# R7FA2A2AD register map
Vendor: Renesas Electronics Corporation; Series: RA2A2; File version: 1.20.02
CPU: CM23 r1p0, little endian, MPU, no FPU, VTOR, 2 interrupt priority bits, 32 interrupts
Registers are 8-bit, read-write, reset 0x0 unless marked. A register's access mark holds for its fields unless they carry their own. Offsets are from the block's base; [hi:lo] are bit positions; {n}, {i} and the like mark numbered series; 'fields as' and 'values as' point back to an identical list; <NAME> marks a mode.

## SYSC — System Control
Base 0x4001E000
0x0C SBYCR 16-bit — Standby Control Register
  [15] SSBY — Software Standby Mode Select
    0=Sleep mode; 1=Software Standby mode
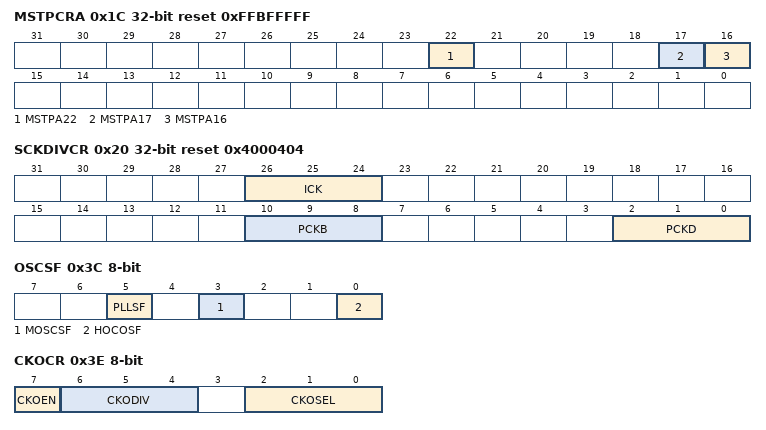
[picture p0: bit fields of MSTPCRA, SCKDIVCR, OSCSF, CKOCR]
0x1C MSTPCRA 32-bit reset 0xFFBFFFFF — Module Stop Control Register A
  [22] MSTPA22 — DTC Module Stop
    0=Cancel the module-stop state; 1=Enter the module-stop state
  [17] MSTPA17 — Main Oscillation Stop Detection for SDADCCLK Module Stop
    0=Supply input clock. SFR used by MOSTD can be read/written.; 1=Stop supply of input clock. SFR used by MOSTD cannot be written. MOSTD clock is stopped and error flag is in the reset status.
  [16] MSTPA16 — Sub Oscillation Stop Detection for SDADCCLK Module Stop
    0=Supply input clock. SFR used by SOSTD can be read/written.; 1=Stop supply of input clock. SFR used by SOSTD cannot be written. SOSTD clock is stopped and error flag is in the reset status.
0x20 SCKDIVCR 32-bit reset 0x4000404 — System Clock Division Control Register
  [all] fields
    0=x 1/1; 1=x 1/2; 2=x 1/4; 3=x 1/8; 4=x 1/16; 5=x 1/32; 6=x 1/64; other=Others (Settings prohibited)
  [26:24] ICK — System Clock (ICLK) Select
  [10:8] PCKB — Peripheral Module Clock B (PCLKB) Select
  [2:0] PCKD — Peripheral Module Clock D (PCLKD) Select
0x26 SCKSCR reset 0x1 — System Clock Source Control Register
  [2:0] CKSEL — Clock Source Select
    0=HOCO; 1=MOCO; 2=LOCO; 3=Main clock oscillator (MOSC); 4=Sub-clock oscillator (SOSC); 5=Setting prohibited; 6=Setting prohibited; 7=Setting prohibited
0x28 PLLCCR 16-bit reset 0x9E04 — PLL Clock Control Register
  [15:8] PLLMUL — PLL Frequency Multiplication Factor Select
    158=× 732 (value after reset); 207=× 781; other=Others (Setting prohibited)
0x2A PLLCR reset 0x1 — PLL Control Register
  [0] PLLSTP — PLL Stop Control
    0=PLL is operating; 1=PLL is stopped
0x31 MEMWAIT — Memory Wait Cycle Control Register for Code Flash
  [0] MEMWAIT — Memory Wait Cycle Select for Code Flash
    0=No wait; 1=Wait
0x32 MOSCCR reset 0x1 — Main Clock Oscillator Control Register
  [0] MOSTP — Main Clock Oscillator Stop
    0=Operate the main clock oscillator; 1=Stop the main clock oscillator
0x36 HOCOCR (reset mask 0xFE) — High-Speed On-Chip Oscillator Control Register
  [0] HCSTP — HOCO Stop
    0=Operate the HOCO clock; 1=Stop the HOCO clock
0x38 MOCOCR — Middle-Speed On-Chip Oscillator Control Register
  [0] MCSTP — MOCO Stop
    0=MOCO clock is operating; 1=MOCO clock is stopped
0x3C OSCSF ro (reset mask 0xFE) — Oscillation Stabilization Flag Register
  [5] PLLSF — PLL Clock Oscillation Stabilization Flag
    0=The PLL clock is stopped or oscillation of the PLL clock is not yet stable; 1=The PLL clock is stable, so is available for use as the SDADCCLK clock
  [3] MOSCSF — Main Clock Oscillation Stabilization Flag
    0=The main clock oscillator is stopped (MOSTP = 1) or is not yet stable; 1=The main clock oscillator is stable, so is available for use as the system clock
  [0] HOCOSF — HOCO Clock Oscillation Stabilization Flag
    0=The HOCO clock is stopped or is not yet stable; 1=The HOCO clock is stable, so is available for use as the system clock
0x3E CKOCR — Clock Out Control Register
  [7] CKOEN — Clock Out Enable
    0=Disable clock out; 1=Enable clock out
  [6:4] CKODIV — Clock Output Frequency Division Ratio
    0=x 1/1; 1=x 1/2; 2=x 1/4; 3=x 1/8; 4=x 1/16; 5=x 1/32; 6=x 1/64; 7=x 1/128
  [2:0] CKOSEL — Clock Out Source Select
    0=HOCO (value after reset); 1=MOCO; 2=LOCO; 3=MOSC; 4=SOSC; 5=PLL; other=Others (Setting prohibited)
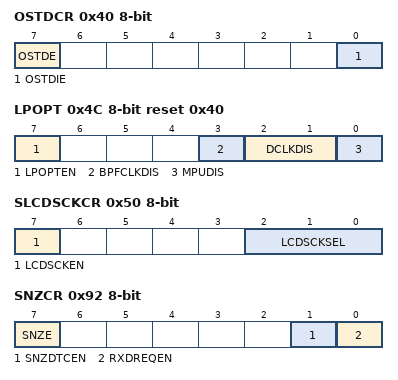
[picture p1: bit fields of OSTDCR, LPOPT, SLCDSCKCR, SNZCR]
0x40 OSTDCR — Oscillation Stop Detection Control Register
  [7] OSTDE — Oscillation Stop Detection Function Enable
    0=Disable oscillation stop detection function; 1=Enable oscillation stop detection function
  [0] OSTDIE — Oscillation Stop Detection Interrupt Enable
    0=Disable oscillation stop detection interrupt (do not notify the POEG); 1=Enable oscillation stop detection interrupt (notify the POEG)
0x41 OSTDSR — Oscillation Stop Detection Status Register
  [0] OSTDF — Oscillation Stop Detection Flag
    0=Main clock oscillation stop not detected; 1=Main clock oscillation stop detected
0x4C LPOPT reset 0x40 — Lower Power Operation Control Register
  [7] LPOPTEN — Lower Power Operation Enable
    0=All lower power counter measure disable; 1=All lower power counter measure enable
  [3] BPFCLKDIS — BPF Clock Disable Control
    0=Flash register R/W clock operates as normal; 1=Flash register R/W clock stops
  [2:1] DCLKDIS — Debug Clock Disable Control
    0=Debug clock does not stop; other=Others (Debug clock stops (valid only when LPOPT.LPOPTEN = 1))
  [0] MPUDIS — MPU Clock Disable Control
    0=MPU operates as normal; 1=MPU operate clock stops (MPU function disable)
0x50 SLCDSCKCR — Segment LCD Source Clock Control Register
  [7] LCDSCKEN — LCD Source Clock Out Enable
    0=LCD source clock out disabled; 1=LCD source clock out enabled
  [2:0] LCDSCKSEL — LCD Source Clock (LCDSRCCLK) Select
    0=LOCO; 1=SOSC; 2=MOSC; 3=MOCO; 4=HOCO; other=Others (Setting prohibited)
0x61 MOCOUTCR — MOCO User Trimming Control Register
  [7:0] MOCOUTRM — MOCO User Trimming
0x62 HOCOUTCR — HOCO User Trimming Control Register
  [7:0] HOCOUTRM — HOCO User Trimming
0x92 SNZCR — Snooze Control Register
  [7] SNZE — Snooze mode Enable
    0=Disable Snooze mode; 1=Enable Snooze mode
  [1] SNZDTCEN — DTC Enable in Snooze mode
    0=Disable DTC operation; 1=Enable DTC operation
  [0] RXDREQEN — RXD0 Snooze Request Enable
    0=Ignore RXD0 falling edge in Software Standby mode; 1=Detect RXD0 falling edge in Software Standby mode
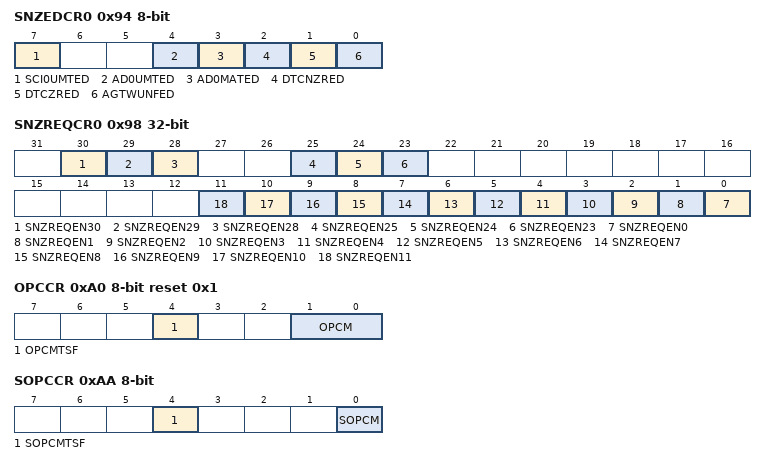
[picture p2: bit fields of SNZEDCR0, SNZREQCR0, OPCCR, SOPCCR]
0x94 SNZEDCR0 — Snooze End Control Register 0
  [all] fields
    0=Disable the snooze end request; 1=Enable the snooze end request
  [7] SCI0UMTED — SCI0 Address Mismatch Snooze End Enable
  [4] AD0UMTED — ADC12 Compare Mismatch Snooze End Enable
  [3] AD0MATED — ADC12 Compare Match Snooze End Enable
  [2] DTCNZRED — Not Last DTC Transmission Completion Snooze End Enable
  [1] DTCZRED — Last DTC Transmission Completion Snooze End Enable
  [0] AGTWUNFED — AGTW1 Underflow Snooze End Enable
0x98 SNZREQCR0 32-bit — Snooze Request Control Register 0
  [all] fields
    0=Disable the snooze request; 1=Enable the snooze request
  [30] SNZREQEN30 — Enable AGTW1 Compare Match B Snooze Request
  [29] SNZREQEN29 — Enable AGTW1 Compare Match A Snooze Request
  [28] SNZREQEN28 — Enable AGTW1 Underflow Snooze Request
  [25] SNZREQEN25 — Enable RTC Period Snooze Request
  [24] SNZREQEN24 — Enable RTC Alarm 0 Snooze Request
  [23] SNZREQEN23 — Enable RTC Alarm 1 Snooze Request
  [n] SNZREQEN{n} (n=0..11) — Enable IRQ{n} Pin Snooze Request
0x9F PSMCR — Power Save Memory Control Register
  [1:0] PSMC — Power Save Memory Control
    0=All SRAMs are on in Software Standby mode; 1=8 KB SRAM (0x2000_4000 to 0x2000_5FFF) is on in Software Standby mode; 2=Setting prohibited; 3=Setting prohibited
0xA0 OPCCR reset 0x1 — Operating Power Control Register
  [4] OPCMTSF ro — Operating Power Control Mode Transition Status Flag
    0=Transition completed; 1=During transition
  [1:0] OPCM — Operating Power Control Mode Select
    0=High-speed mode; 1=Middle-speed mode; 2=Setting prohibited; 3=Low-speed mode
0xA2 MOSCWTCR reset 0x5 — Main Clock Oscillator Wait Control Register
  [3:0] MSTS — Main Clock Oscillator Wait Time Setting
    0=Wait time = 2 cycles (0.25 us); 1=Wait time = 1024 cycles (128 us); 2=Wait time = 2048 cycles (256 us); 3=Wait time = 4096 cycles (512 us); 4=Wait time = 8192 cycles (1024 us); 5=Wait time = 16384 cycles (2048 us); 6=Wait time = 32768 cycles (4096 us); 7=Wait time = 65536 cycles (8192 us); 8=Wait time = 131072 cycles (16384 us); 9=Wait time = 262144 cycles (32768 us); other=Others (Setting prohibited)
0xA5 HOCOWTCR reset 0x5 — High-Speed On-Chip Oscillator Wait Control Register
  [2:0] HSTS — HOCO Wait Time Setting
    5=Value after reset; 3=Before starting high-speed on-chip oscillator by setting HOCOCR.HCSTP bit, the HSTS[2:0] bits must be set to 011b beforehand. Wait time = 46 cycles (5.75 µs) Wait time is calculated at MOCO = 8 MHz (typically 0.125 µs).; other=Others (Setting prohibited)
0xAA SOPCCR — Sub Operating Power Control Register
  [4] SOPCMTSF ro — Operating Power Control Mode Transition Status Flag
    0=Transition completed; 1=During transition
  [0] SOPCM — Sub Operating Power Control Mode Select
    0=Other than Subosc-speed mode; 1=Subosc-speed mode
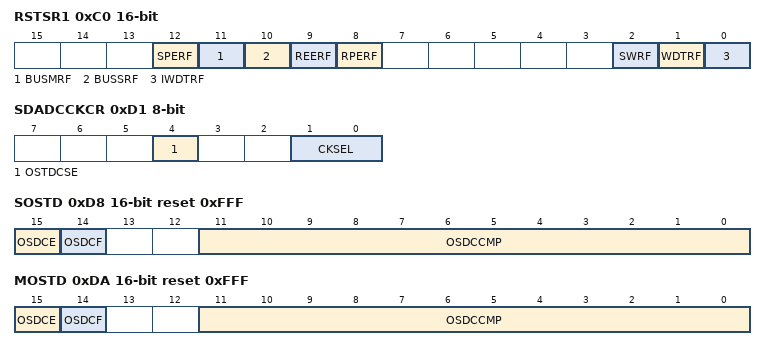
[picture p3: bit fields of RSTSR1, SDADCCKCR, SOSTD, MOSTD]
0xC0 RSTSR1 16-bit (reset mask 0xE0F8) — Reset Status Register 1
  [12] SPERF — CPU Stack Pointer Error Reset Detect Flag
    0=CPU stack pointer error reset not detected; 1=CPU stack pointer error reset detected
  [11] BUSMRF — Bus Master MPU Error Reset Detect Flag
    0=Bus master MPU error reset not detected; 1=Bus master MPU error reset detected
  [10] BUSSRF — Bus Slave MPU Error Reset Detect Flag
    0=Bus slave MPU error reset not detected; 1=Bus slave MPU error reset detected
  [9] REERF — SRAM ECC Error Reset Detect Flag
    0=SRAM ECC error reset not detected; 1=SRAM ECC error reset detected
  [8] RPERF — SRAM Parity Error Reset Detect Flag
    0=SRAM parity error reset not detected; 1=SRAM parity error reset detected
  [2] SWRF — Software Reset Detect Flag
    0=Software reset not detected; 1=Software reset detected
  [1] WDTRF — Watchdog Timer Reset Detect Flag
    0=Watchdog timer reset not detected; 1=Watchdog timer reset detected
  [0] IWDTRF — Independent Watchdog Timer Reset Detect Flag
    0=Independent watchdog timer reset not detected; 1=Independent watchdog timer reset detected
0xD1 SDADCCKCR — 24-bit Sigma-delta A/D Converter Clock Control Register
  [4] OSTDCSE — Clock Switch Enable for Oscillation Stop Detected
    0=Not switched to HOCO when oscillation stop detected; 1=Switched to HOCO, when oscillation stop detected
  [1:0] CKSEL — 24-bit Sigma-delta A/D Converter Clock Select
    0=MOSC; 1=HOCO; 2=PLL; other=Others (Setting prohibited)
0xD8 SOSTD 16-bit reset 0xFFF — Sub Clock Oscillation Stop Detection Control Register
  [15] OSDCE — Control of Oscillation Stop Detector Operation
    0=Stop operation of the oscillation stop detector; 1=Start operation of the oscillation stop detector
  [14] OSDCF ro — Status of Oscillation Stop Detector Operation
    0=Stop operation of the oscillation stop detector; 1=Run operation of the oscillation stop detector
  [11:0] OSDCCMP — Oscillation Stop Detection Time
0xDA MOSTD 16-bit reset 0xFFF — Main Oscillation Stop Detection Control Register
  fields as SOSTD
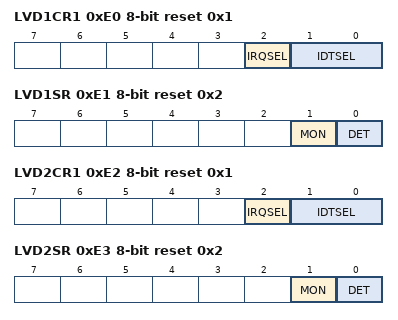
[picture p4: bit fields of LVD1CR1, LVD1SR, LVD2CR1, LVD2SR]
0xE0 LVD1CR1 reset 0x1 — Voltage Monitor 1 Circuit Control Register
  [2] IRQSEL — Voltage Monitor 1 Interrupt Type Select
    0=Non-maskable interrupt; 1=Maskable interrupt
  [1:0] IDTSEL — Voltage Monitor 1 Interrupt Generation Condition Select
    0=When VCC >= Vdet1 (rise) is detected; 1=When VCC < Vdet1 (fall) is detected; 2=When fall and rise are detected; 3=Settings prohibited
0xE1 LVD1SR reset 0x2 — Voltage Monitor 1 Circuit Status Register
  [1] MON ro — Voltage Monitor 1 Signal Monitor Flag
    0=VCC < Vdet1; 1=VCC >= Vdet1 or MON is disabled
  [0] DET — Voltage Monitor 1 Voltage Variation Detection Flag
    0=Not detected; 1=Vdet1 crossing is detected
0xE2 LVD2CR1 reset 0x1 — Voltage Monitor 2 Circuit Control Register 1
  [2] IRQSEL — Voltage Monitor 2 Interrupt Type Select
    0=Non-maskable interrupt; 1=Maskable interrupt
  [1:0] IDTSEL — Voltage Monitor 2 Interrupt Generation Condition Select
    0=When VCC >= Vdet2 (rise) is detected; 1=When VCC < Vdet2 (fall) is detected; 2=When fall and rise are detected; 3=Settings prohibited
0xE3 LVD2SR reset 0x2 — Voltage Monitor 2 Circuit Status Register
  [1] MON ro — Voltage Monitor 2 Signal Monitor Flag
    0=VCC < Vdet2; 1=VCC >= Vdet2 or MON is disabled
  [0] DET — Voltage Monitor 2 Voltage Variation Detection Flag
    0=Not detected; 1=Vdet2 crossing is detected
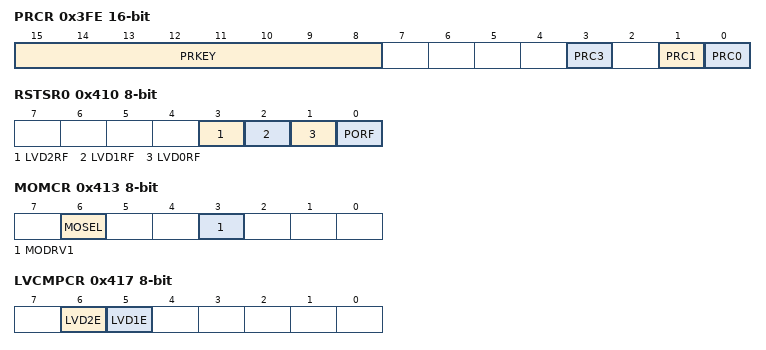
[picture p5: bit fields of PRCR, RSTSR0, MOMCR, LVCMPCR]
0x3FE PRCR 16-bit — Protect Register
  [15:8] PRKEY wo — PRC Key Code
  [3] PRC3 — Enable writing to the registers related to the LVD
    0=Disable writes; 1=Enable writes
  [1] PRC1 — Enable writing to the registers related to the low power modes
    0=Disable writes; 1=Enable writes
  [0] PRC0 — Enable writing to the registers related to the clock generation circuit
    0=Disable writes; 1=Enable writes
0x40E SYOCDCR — System Control OCD Control Register
  [7] DBGEN — Debugger Enable bit
    0=On-chip debugger is disabled; 1=On-chip debugger is enabled
0x410 RSTSR0 (reset mask 0xF0) — Reset Status Register 0
  [3] LVD2RF — Voltage Monitor 2 Reset Detect Flag
    0=Voltage monitor 2 reset not detected; 1=Voltage monitor 2 reset detected
  [2] LVD1RF — Voltage Monitor 1 Reset Detect Flag
    0=Voltage monitor 1 reset not detected; 1=Voltage monitor 1 reset detected
  [1] LVD0RF — Voltage Monitor 0 Reset Detect Flag
    0=Voltage monitor 0 reset not detected; 1=Voltage monitor 0 reset detected
  [0] PORF — Power-On Reset Detect Flag
    0=Power-on reset not detected; 1=Power-on reset detected
0x411 RSTSR2 (reset mask 0xFE) — Reset Status Register 2
  [0] CWSF — Cold/Warm Start Determination Flag
    0=Cold start; 1=Warm start
0x413 MOMCR — Main Clock Oscillator Mode Oscillation Control Register
  [6] MOSEL — Main Clock Oscillator Switching
    0=Resonator; 1=External clock input
  [3] MODRV1 — Main Clock Oscillator Drive Capability 1 Switching
    0=10 MHz to 20 MHz; 1=1 MHz to 10 MHz
0x417 LVCMPCR — Voltage Monitor Circuit Control Register
  [6] LVD2E — Voltage Detection 2 Enable
    0=Voltage detection 2 circuit disabled; 1=Voltage detection 2 circuit enabled
  [5] LVD1E — Voltage Detection 1 Enable
    0=Voltage detection 1 circuit disabled; 1=Voltage detection 1 circuit enabled
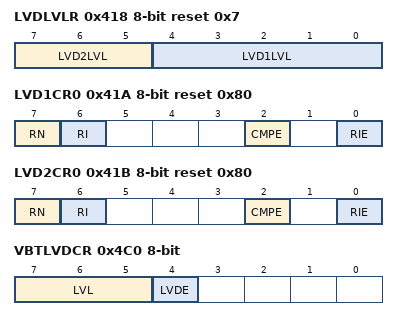
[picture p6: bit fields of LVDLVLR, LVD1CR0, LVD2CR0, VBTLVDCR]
0x418 LVDLVLR reset 0x7 — Voltage Detection Level Select Register
  [7:5] LVD2LVL — Voltage Detection 2 Level Select (Standard voltage during fall in voltage)
    {v}=Vdet2_{v} (v=0..3); other=Others (Setting prohibited)
  [4:0] LVD1LVL — Voltage Detection 1 Level Select (Standard voltage during fall in voltage)
    {v}=Vdet1_{v} (v=0..9); 10=Vdet1_A; 11=Vdet1_B; 12=Vdet1_C; 13=Vdet1_D; 14=Vdet1_E; 15=Vdet1_F; other=Others (Setting prohibited)
0x41A LVD1CR0 reset 0x80 — Voltage Monitor 1 Circuit Control Register 0
  [7] RN — Voltage Monitor 1 Reset Negate Select
    0=Negate after a stabilization time (tLVD1) when VCC > Vdet1 is detected; 1=Negate after a stabilization time (tLVD1) on assertion of the LVD1 reset
  [6] RI — Voltage Monitor 1 Circuit Mode Select
    0=Generate voltage monitor 1 interrupt on Vdet1 crossing; 1=Enable voltage monitor 1 reset when the voltage falls to and below Vdet1
  [2] CMPE — Voltage Monitor 1 Circuit Comparison Result Output Enable
    0=Disable voltage monitor 1 circuit comparison result output; 1=Enable voltage monitor 1 circuit comparison result output
  [0] RIE — Voltage Monitor 1 Interrupt/Reset Enable
    0=Disable; 1=Enable
0x41B LVD2CR0 reset 0x80 — Voltage Monitor 2 Circuit Control Register 0
  [7] RN — Voltage Monitor 2 Reset Negate Select
    0=Negate after a stabilization time (tLVD2) when VCC > Vdet2 is detected; 1=Negate after a stabilization time (tLVD2) on assertion of the LVD2 reset
  [6] RI — Voltage Monitor 2 Circuit Mode Select
    0=Generate voltage monitor 2 interrupt on Vdet2 crossing; 1=Enable voltage monitor 2 reset when the voltage falls to and below Vdet2
  [2] CMPE — Voltage Monitor 2 Circuit Comparison Result Output Enable
    0=Disable voltage monitor 2 circuit comparison result output; 1=Enable voltage monitor 2 circuit comparison result output
  [0] RIE — Voltage Monitor 2 Interrupt/Reset Enable
    0=Disable; 1=Enable
0x480 SOSCCR reset 0x1 — Sub-Clock Oscillator Control Register
  [0] SOSTP — Sub Clock Oscillator Stop
    0=Operate the sub-clock oscillator; 1=Stop the sub-clock oscillator
0x481 SOMCR — Sub-Clock Oscillator Mode Control Register
  [1:0] SODRV — Sub-Clock Oscillator Drive Capability Switching
    0=Normal Mode; 1=Low Power Mode 1; 2=Low Power Mode 2; 3=Low Power Mode 3
0x482 SOMRG — Sub-Clock Oscillator Margin Check Register
  [1:0] SOSCMRG — Sub Clock Oscillator Margin Check Switching
    0=Normal current; 1=Lower margin check; 2=Upper margin check; 3=Setting prohibited
0x490 LOCOCR — Low-Speed On-Chip Oscillator Control Register
  [0] LCSTP — LOCO Stop
    0=Operate the LOCO clock; 1=Stop the LOCO clock
0x492 LOCOUTCR — LOCO User Trimming Control Register
  [7:0] LOCOUTRM — LOCO User Trimming
0x4C0 VBTLVDCR — EXLVDVBAT Circuit Control Register
  [7:5] LVL — EXLVDVBAT Pin Low Voltage Detect Level Select
    0=2.2 V; 1=2.4 V; 2=2.6 V; 3=2.7 V; 4=2.8 V; 5=2.9 V; 6=3.1 V; 7=Setting prohibited
  [4] LVDE — EXLVDVBAT Pin Low Voltage Detect Enable
    0=EXLVDVBAT pin low voltage detection disabled; 1=EXLVDVBAT pin low voltage detection enabled
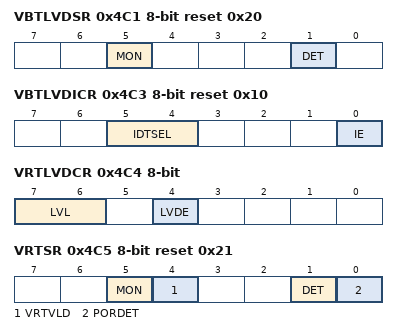
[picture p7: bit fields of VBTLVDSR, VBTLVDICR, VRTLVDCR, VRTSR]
0x4C1 VBTLVDSR reset 0x20 — EXLVDVBAT Circuit Status Register
  [5] MON ro — EXLVDVBAT Pin Low Voltage Monitor Flag
    0=EXLVDVBAT < Vdet_lvdvbat; 1=EXLVDVBAT ≥ Vdet_lvdvbat or MON is disabled
  [1] DET — EXLVDVBAT Pin Low Voltage Detect Flag
    0=EXLVDVBAT pin low voltage not detected; 1=EXLVDVBAT pin low voltage detected
0x4C2 VBTCMPCR — EXLVDVBAT Comparator Control Register
  [0] CMPE — EXLVDVBAT Pin Low Voltage Detect Circuit Output Enable
    0=EXLVDVBAT pin low voltage detect circuit output disabled; 1=EXLVDVBAT pin low voltage detect circuit output enabled
0x4C3 VBTLVDICR reset 0x10 — EXLVDVBAT Pin Low Voltage Detect Interrupt Control Register
  [5:4] IDTSEL — EXLVDVBAT Pin Low Voltage Detect Interrupt Generation Condition Select
    0=When EXLVDVBAT > Vdet_lvdvbat (rise) is detected; 1=When EXLVDVBAT < Vdet_lvdvbat (fall) is detected; 2=When fall and rise are detected; 3=Settings prohibited
  [0] IE — EXLVDVBAT Pin Low Voltage Detect Interrupt Enable
    0=EXLVDVBAT pin low voltage detection interrupt disabled; 1=EXLVDVBAT pin low voltage detection interrupt enabled
0x4C4 VRTLVDCR — LVDVRTC Circuit Control Register
  [7:6] LVL — VRTC Pin Low Voltage Detect Level Select
    0=2.2 V; 1=2.4 V; 2=2.6 V; 3=2.8 V
  [4] LVDE — VRTC Pin Low Voltage Detect Enable
    0=VRTC pin low voltage detection disabled; 1=VRTC pin low voltage detection enabled
0x4C5 VRTSR reset 0x21 — VRTC Status Register
  [5] MON ro — VRTC Signal Monitor Flag
    0=VRTC < Vdet_vrtc; 1=VRTC ≥ Vdet_vrtc or MON is disabled
  [4] VRTVLD ro — VRTC-domain Valid
    0=VRTC-domain area not valid; 1=VRTC-domain area valid
  [1] DET — VRTC Voltage Variation Detection Flag
    0=Vdet_vrtc crossing not detected; 1=Vdet_vrtc crossing detected
  [0] PORDET — VRTC-domain Power-on Reset Detect Flag
    0=VRTC-domain power-on reset not detected; 1=VRTC-domain power-on reset detected
0x4C6 VRTCMPCR — VRTC Comparator Control Register
  [0] CMPE — VRTC Pin Low Voltage Detect Circuit Output Enable
    0=VRTC pin low voltage detect circuit output disabled; 1=VRTC pin low voltage detect circuit output enabled
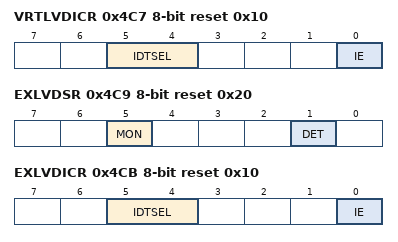
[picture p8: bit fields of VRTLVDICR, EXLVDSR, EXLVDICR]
0x4C7 VRTLVDICR reset 0x10 — VRTC Pin Low Voltage Detect Interrupt Control Register
  [5:4] IDTSEL — VRTC Pin Low Voltage Detect Interrupt Generation Condition Select
    0=When VRTC > Vdet_vrtc (rise) is detected; 1=When VRTC < Vdet_vrtc (fall) is detected; 2=When fall and rise are detected; 3=Settings prohibited
  [0] IE — VRTC Pin Low Voltage Detect Interrupt Enable
    0=VRTC pin low voltage detection interrupt disabled; 1=VRTC pin low voltage detection interrupt enabled
0x4C8 EXLVDCR — EXLVD Circuit Control Register
  [4] LVDE — EXLVD Pin Low Voltage Detect Enable
    0=EXLVD pin low voltage detection disabled; 1=EXLVD pin low voltage detection enabled
0x4C9 EXLVDSR reset 0x20 — EXLVD Circuit Status Register
  [5] MON ro — EXLVD pin Low Voltage Monitor Flag
    0=EXLVD < Vdet_exlvd; 1=EXLVD ≥ Vdet_exlvd or MON is disabled
  [1] DET — EXLVD pin Low Voltage Detect Flag
    0=EXLVD pin low voltage not detected; 1=EXLVD pin low voltage detected
0x4CA EXLVDCMPCR — EXLVD Comparator Control Register
  [0] CMPE — EXLVD Pin Low Voltage Detect Circuit Output Enable
    0=EXLVD pin low voltage detect circuit output disabled; 1=EXLVD pin low voltage detect circuit output enabled
0x4CB EXLVDICR reset 0x10 — EXLVD Pin Low Voltage Detect Interrupt Control Register
  [5:4] IDTSEL — EXLVD Pin Low Voltage Detect Interrupt Generation Condition Select
    0=When EXLVD > Vdet_exlvd (rise) is detected; 1=When EXLVD < Vdet_exlvd (fall) is detected; 2=When fall and rise are detected; 3=Settings prohibited
  [0] IE — EXLVD Pin Low Voltage Detect Interrupt Enable
    0=EXLVD pin low voltage detection interrupt disabled; 1=EXLVD pin low voltage detection interrupt enabled
